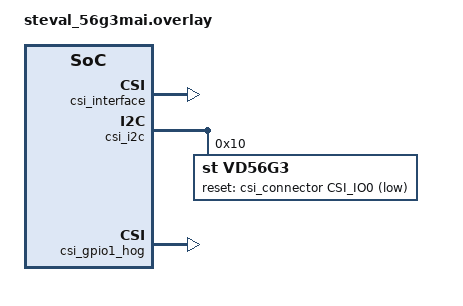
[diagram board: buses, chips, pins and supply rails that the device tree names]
/*
 * SPDX-FileCopyrightText: Copyright The Zephyr Project Contributors
 * SPDX-FileCopyrightText: Copyright (c) 2026 LANDROVAL
 *
 * SPDX-License-Identifier: Apache-2.0
 *
 * STEVAL-56G3MAI shield overlay (Raspberry Pi 22-pin FFC CSI-2 connector).
 */

#include <zephyr/dt-bindings/gpio/raspberrypi-csi-connector.h>
#include <zephyr/dt-bindings/video/video-interfaces.h>
#include <freq.h>

/ {
	chosen {
		zephyr,camera = &csi_capture_port;
	};

	vd56g3_input_clock: vd56g3-input-clock {
		compatible = "fixed-clock";
		/* CLKIN on the Pi-compatible CSI connector ([6..27] MHz). */
		clock-frequency = <DT_FREQ_M(12)>;
		#clock-cells = <0>;
	};
};

&csi_interface {
	status = "okay";
};

&csi_ep_in {
	remote-endpoint-label = "vd56g3_ep_out";
	bus-type = <VIDEO_BUS_TYPE_CSI2_DPHY>;
	data-lanes = <1 2>;
};

&csi_i2c {
	status = "okay";

	vd56g3: camera@10 {
		compatible = "st,vd56g3";
		reg = <0x10>;
		clocks = <&vd56g3_input_clock>;
		reset-gpios = <&csi_connector CSI_IO0 GPIO_ACTIVE_LOW>;
		/*
		 * Raspberry Pi connector standard: lane P/N pairs are swapped
		 * vs. the sensor default (see shield documentation).
		 */
		st,csi-lane0-polarity-invert;
		st,csi-lane1-polarity-invert;
		st,csi-clock-polarity-invert;

		port {
			vd56g3_ep_out: endpoint {
				remote-endpoint-label = "csi_ep_in";
				bus-type = <VIDEO_BUS_TYPE_CSI2_DPHY>;
				data-lanes = <1 2>;
			};
		};
	};
};

&csi_gpio1_hog {
	status = "okay";
	output-high;
};
